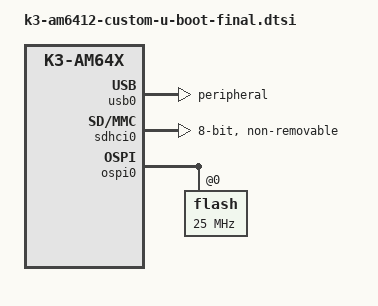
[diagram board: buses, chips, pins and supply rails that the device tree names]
/* Final U-Boot/SPL candidate for CPU_BRD_V03_PBA_260511. */
#include "k3-am64x-binman.dtsi"
#include "../base/k3-am6412-custom-u-boot-spl.dtsi"

/ {
	chosen {
		tick-timer = &main_timer0;
	};
};

&main_timer0 {
	clock-frequency = <200000000>;
};

&uboot_uart0_early_pins_default {
	bootph-all;
};

&uboot_ospi0_early_pins_default {
	bootph-all;
};

&uboot_mcu_uart0_early_pins_default {
	bootph-all;
};

&main_uart0 {
	bootph-all;
};

&usb0 {
	dr_mode = "peripheral";
	bootph-all;
};

&sdhci0 {
	bootph-all;
	bus-width = <8>;
	non-removable;
};

&sdhci1 {
	status = "disabled";
};

&ospi0 {
	bootph-all;

	flash@0 {
		bootph-all;
		spi-tx-bus-width = <1>;
		spi-rx-bus-width = <1>;
		spi-max-frequency = <25000000>;
	};
};

/* TODO: choose final boot priority between eMMC and OSPI for production images. */
/* TODO: add DDR include chain after LPDDR4 timing/training source is finalized. */
/* TODO: add binman/package integration once board boot flow is frozen. */
/* TODO: enable octal/DQS profile only after Boot ROM/SPL root cause is resolved. */
/* TODO: keep SERDES0 disabled in U-Boot until USB3/PCIe policy is fixed. */
